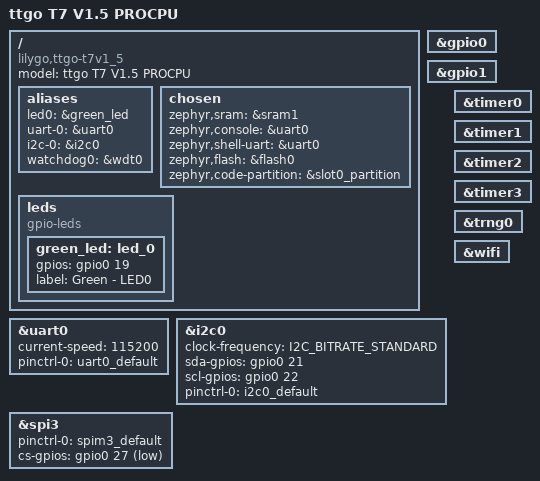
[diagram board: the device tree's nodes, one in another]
/*
 * Copyright 2024 Tobias Kässer <t.kaesser@gmail.com>
 *
 * SPDX-License-Identifier: Apache-2.0
 */
/dts-v1/;

#include <espressif/esp32/esp32_wrover_e_n4r8.dtsi>
#include <espressif/partitions_0x1000_amp.dtsi>
#include "ttgo_t7v1_5-pinctrl.dtsi"
#include <zephyr/dt-bindings/input/input-event-codes.h>

/ {
	model = "ttgo T7 V1.5 PROCPU";
	compatible = "lilygo,ttgo-t7v1_5";

	aliases {
		led0 = &green_led;
		uart-0 = &uart0;
		i2c-0 = &i2c0;
		watchdog0 = &wdt0;
	};

	chosen {
		zephyr,sram = &sram1;
		zephyr,console = &uart0;
		zephyr,shell-uart = &uart0;
		zephyr,flash = &flash0;
		zephyr,code-partition = &slot0_partition;
	};

	leds {
		compatible = "gpio-leds";

		green_led: led_0 {
			gpios =  <&gpio0 19 GPIO_ACTIVE_HIGH>;
			label = "Green - LED0";
		};
	};
};

&uart0 {
	status = "okay";
	current-speed = <115200>;
	pinctrl-0 = <&uart0_default>;
	pinctrl-names = "default";
};

&gpio0 {
	status = "okay";
};

&gpio1 {
	status = "okay";
};

/* OLED display */
&i2c0 {
	status = "okay";
	clock-frequency = <I2C_BITRATE_STANDARD>;
	sda-gpios = <&gpio0 21 GPIO_OPEN_DRAIN>;
	scl-gpios = <&gpio0 22 GPIO_OPEN_DRAIN>;
	pinctrl-0 = <&i2c0_default>;
	pinctrl-names = "default";
};

&spi3 {
	#address-cells = <1>;
	#size-cells = <0>;
	status = "okay";
	pinctrl-0 = <&spim3_default>;
	pinctrl-names = "default";
	cs-gpios = <&gpio0 27 GPIO_ACTIVE_LOW>;
};

&timer0 {
	status = "okay";
};

&timer1 {
	status = "okay";
};

&timer2 {
	status = "okay";
};

&timer3 {
	status = "okay";
};

&trng0 {
	status = "okay";
};

&wifi {
	status = "okay";
};
